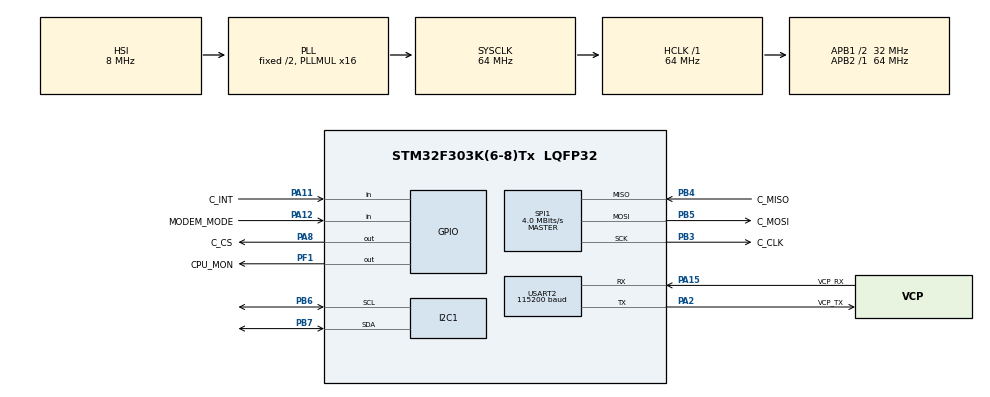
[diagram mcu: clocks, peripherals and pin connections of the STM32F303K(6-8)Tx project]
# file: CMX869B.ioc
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FREERTOS.Tasks01=TaskHK,24,128,StartTaskHK,Default,NULL,Static,TaskHKBuffer,TaskHKControlBlock;TaskCMX869B,48,128,StartTaskCMX869B,Default,NULL,Static,TaskCMX869BBuffer,TaskCMX869BControlBlock
I2C1.Timing=0x10B17DB5
Mcu.Family=STM32F3
Mcu.Name=STM32F303K(6-8)Tx
Mcu.Package=LQFP32
NVIC.PriorityGroup=NVIC_PRIORITYGROUP_4
NVIC.TIM2_IRQn=true\:5\:0\:false\:false\:true\:true\:true\:true\:true
NVIC.TIM6_DAC1_IRQn=true\:15\:0\:false\:false\:true\:false\:false\:true\:true
NVIC.TimeBase=TIM6_DAC1_IRQn
NVIC.TimeBaseIP=TIM6
NVIC.USART2_IRQn=true\:5\:0\:false\:false\:true\:true\:true\:true\:true
PA11.GPIO_Label=C_INT
PA11.Signal=GPIO_Input
PA12.GPIO_Label=MODEM_MODE
PA12.GPIO_PuPd=GPIO_PULLUP
PA12.Signal=GPIO_Input
PA13.GPIO_Label=SWDIO
PA13.Mode=Serial_Wire
PA13.Signal=SYS_JTMS-SWDIO
PA14.GPIO_Label=SWCLK
PA14.Mode=Serial_Wire
PA14.Signal=SYS_JTCK-SWCLK
PA15.GPIO_Label=VCP_RX
PA15.Mode=Asynchronous
PA15.Signal=USART2_RX
PA2.GPIO_Label=VCP_TX
PA2.Mode=Asynchronous
PA2.Signal=USART2_TX
PA8.GPIO_Label=C_CS
PA8.PinState=GPIO_PIN_SET
PA8.Signal=GPIO_Output
PB3.GPIO_Label=C_CLK
PB3.Mode=Full_Duplex_Master
PB3.Signal=SPI1_SCK
PB4.GPIO_Label=C_MISO
PB4.GPIO_PuPd=GPIO_PULLDOWN
PB4.Mode=Full_Duplex_Master
PB4.Signal=SPI1_MISO
PB5.GPIO_Label=C_MOSI
PB5.Mode=Full_Duplex_Master
PB5.Signal=SPI1_MOSI
PB6.Mode=I2C
PB6.Signal=I2C1_SCL
PB7.Mode=I2C
PB7.Signal=I2C1_SDA
PF0\ /\ OSC_IN.GPIO_Label=MCO
PF0\ /\ OSC_IN.Mode=HSE-External-Clock-Source
PF0\ /\ OSC_IN.Signal=RCC_OSC_IN
PF1\ /\ OSC_OUT.GPIO_Label=CPU_MON
PF1\ /\ OSC_OUT.Signal=GPIO_Output
ProjectManager.HeapSize=0x200
ProjectManager.StackSize=0x400
ProjectManager.TargetToolchain=CMake
RCC.AHBFreq_Value=64000000
RCC.APB1CLKDivider=RCC_HCLK_DIV2
RCC.APB1Freq_Value=32000000
RCC.APB1TimFreq_Value=64000000
RCC.APB2Freq_Value=64000000
RCC.APB2TimFreq_Value=64000000
RCC.CortexFreq_Value=64000000
RCC.HCLKFreq_Value=64000000
RCC.HSE_VALUE=8000000
RCC.HSI_VALUE=8000000
RCC.I2c1ClockSelection=RCC_I2C1CLKSOURCE_SYSCLK
RCC.PLLMUL=RCC_PLL_MUL16
RCC.SYSCLKFreq_VALUE=64000000
RCC.SYSCLKSourceVirtual=RCC_SYSCLKSOURCE_PLLCLK
SPI1.BaudRatePrescaler=SPI_BAUDRATEPRESCALER_16
SPI1.CalculateBaudRate=4.0 MBits/s
SPI1.DataSize=SPI_DATASIZE_8BIT
SPI1.Direction=SPI_DIRECTION_2LINES
SPI1.Mode=SPI_MODE_MASTER
SPI1.VirtualType=VM_MASTER
TIM2.AutoReloadPreload=TIM_AUTORELOAD_PRELOAD_ENABLE
TIM2.Period=53333
TIM2.Prescaler=0
USART2.BaudRate=115200
USART2.VirtualMode-Asynchronous=VM_ASYNC
VP_FREERTOS_VS_CMSIS_V2.Mode=CMSIS_V2
VP_SYS_VS_tim6.Mode=TIM6
VP_TIM2_VS_ClockSourceINT.Mode=Internal
board=NUCLEO-F303K8

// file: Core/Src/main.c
/* USER CODE BEGIN Header */
/**
  ******************************************************************************
  * @file           : main.c
  * @brief          : Main program body
  ******************************************************************************
  * @attention
  *
  * Copyright (c) 2025 STMicroelectronics.
  * All rights reserved.
  *
  * This software is licensed under terms that can be found in the LICENSE file
  * in the root directory of this software component.
  * If no LICENSE file comes with this software, it is provided AS-IS.
  *
  ******************************************************************************
  */
/* USER CODE END Header */
#include "main.h"
#include "cmsis_os.h"

/* USER CODE BEGIN Includes */
#include "task.h"
#include "xprintf.h"
#include "TaskCMX869B.h"
#include "TaskHK.h"

/* USER CODE END Includes */

typedef StaticTask_t osStaticThreadDef_t;

I2C_HandleTypeDef hi2c1;

SPI_HandleTypeDef hspi1;

TIM_HandleTypeDef htim2;

UART_HandleTypeDef huart2;

/* Definitions for TaskHK */
osThreadId_t TaskHKHandle;
uint32_t TaskHKBuffer[ 128 ];
osStaticThreadDef_t TaskHKControlBlock;
const osThreadAttr_t TaskHK_attributes = {
  .name = "TaskHK",
  .cb_mem = &TaskHKControlBlock,
  .cb_size = sizeof(TaskHKControlBlock),
  .stack_mem = &TaskHKBuffer[0],
  .stack_size = sizeof(TaskHKBuffer),
  .priority = (osPriority_t) osPriorityNormal,
};
/* Definitions for TaskCMX869B */
osThreadId_t TaskCMX869BHandle;
uint32_t TaskCMX869BBuffer[ 128 ];
osStaticThreadDef_t TaskCMX869BControlBlock;
const osThreadAttr_t TaskCMX869B_attributes = {
  .name = "TaskCMX869B",
  .cb_mem = &TaskCMX869BControlBlock,
  .cb_size = sizeof(TaskCMX869BControlBlock),
  .stack_mem = &TaskCMX869BBuffer[0],
  .stack_size = sizeof(TaskCMX869BBuffer),
  .priority = (osPriority_t) osPriorityRealtime,
};

void SystemClock_Config(void);
static void MX_GPIO_Init(void);
static void MX_I2C1_Init(void);
static void MX_USART2_UART_Init(void);
static void MX_SPI1_Init(void);
static void MX_TIM2_Init(void);
void StartTaskHK(void *argument);
void StartTaskCMX869B(void *argument);

/* USER CODE BEGIN PFP */
void cbus_entry();

/* USER CODE END PFP */

int main(void)
{

  /* MCU Configuration--------------------------------------------------------*/

  /* Reset of all peripherals, Initializes the Flash interface and the Systick. */
  HAL_Init();

  /* USER CODE BEGIN Init */
    // OpenOCDのreset-initがPLL(HSI x16)をSYSCLKにしているので、
    // そのままだとSystemClock_Config()のPLL再設定がHAL_ERRORになる。HSIに戻しておく
    HAL_RCC_DeInit();
  /* USER CODE END Init */

  /* Configure the system clock */
  SystemClock_Config();

  /* Initialize all configured peripherals */
  MX_GPIO_Init();
  MX_I2C1_Init();
  MX_USART2_UART_Init();
  MX_SPI1_Init();
  MX_TIM2_Init();
  /* USER CODE BEGIN 2 */
    // xprintの実働関数の登録,uart_putcはCMX869B.cで定義
    xdev_out(uart_putc);
  /* USER CODE END 2 */

  /* Init scheduler */
  osKernelInitialize();

  /* Create the thread(s) */
  /* creation of TaskHK */
  TaskHKHandle = osThreadNew(StartTaskHK, NULL, &TaskHK_attributes);

  /* creation of TaskCMX869B */
  TaskCMX869BHandle = osThreadNew(StartTaskCMX869B, NULL, &TaskCMX869B_attributes);

  /* Start scheduler */
  osKernelStart();

  /* We should never get here as control is now taken by the scheduler */

  /* Infinite loop */

}

void SystemClock_Config(void)
{
  RCC_OscInitTypeDef RCC_OscInitStruct = {0};
  RCC_ClkInitTypeDef RCC_ClkInitStruct = {0};
  RCC_PeriphCLKInitTypeDef PeriphClkInit = {0};

  /** Initializes the RCC Oscillators according to the specified parameters
  * in the RCC_OscInitTypeDef structure.
  */
  RCC_OscInitStruct.OscillatorType = RCC_OSCILLATORTYPE_HSI;
  RCC_OscInitStruct.HSIState = RCC_HSI_ON;
  RCC_OscInitStruct.HSICalibrationValue = RCC_HSICALIBRATION_DEFAULT;
  RCC_OscInitStruct.PLL.PLLState = RCC_PLL_ON;
  RCC_OscInitStruct.PLL.PLLSource = RCC_PLLSOURCE_HSI;
  RCC_OscInitStruct.PLL.PLLMUL = RCC_PLL_MUL16;
  if (HAL_RCC_OscConfig(&RCC_OscInitStruct) != HAL_OK)
  {
    Error_Handler();
  }

  /** Initializes the CPU, AHB and APB buses clocks
  */
  RCC_ClkInitStruct.ClockType = RCC_CLOCKTYPE_HCLK|RCC_CLOCKTYPE_SYSCLK
                              |RCC_CLOCKTYPE_PCLK1|RCC_CLOCKTYPE_PCLK2;
  RCC_ClkInitStruct.SYSCLKSource = RCC_SYSCLKSOURCE_PLLCLK;
  RCC_ClkInitStruct.AHBCLKDivider = RCC_SYSCLK_DIV1;
  RCC_ClkInitStruct.APB1CLKDivider = RCC_HCLK_DIV2;
  RCC_ClkInitStruct.APB2CLKDivider = RCC_HCLK_DIV1;

  if (HAL_RCC_ClockConfig(&RCC_ClkInitStruct, FLASH_LATENCY_2) != HAL_OK)
  {
    Error_Handler();
  }
  PeriphClkInit.PeriphClockSelection = RCC_PERIPHCLK_I2C1;
  PeriphClkInit.I2c1ClockSelection = RCC_I2C1CLKSOURCE_SYSCLK;
  if (HAL_RCCEx_PeriphCLKConfig(&PeriphClkInit) != HAL_OK)
  {
    Error_Handler();
  }
}

static void MX_I2C1_Init(void)
{

  hi2c1.Instance = I2C1;
  hi2c1.Init.Timing = 0x10B17DB5;
  hi2c1.Init.OwnAddress1 = 0;
  hi2c1.Init.AddressingMode = I2C_ADDRESSINGMODE_7BIT;
  hi2c1.Init.DualAddressMode = I2C_DUALADDRESS_DISABLE;
  hi2c1.Init.OwnAddress2 = 0;
  hi2c1.Init.OwnAddress2Masks = I2C_OA2_NOMASK;
  hi2c1.Init.GeneralCallMode = I2C_GENERALCALL_DISABLE;
  hi2c1.Init.NoStretchMode = I2C_NOSTRETCH_DISABLE;
  if (HAL_I2C_Init(&hi2c1) != HAL_OK)
  {
    Error_Handler();
  }

  /** Configure Analogue filter
  */
  if (HAL_I2CEx_ConfigAnalogFilter(&hi2c1, I2C_ANALOGFILTER_ENABLE) != HAL_OK)
  {
    Error_Handler();
  }

  /** Configure Digital filter
  */
  if (HAL_I2CEx_ConfigDigitalFilter(&hi2c1, 0) != HAL_OK)
  {
    Error_Handler();
  }

}

static void MX_SPI1_Init(void)
{

  /* SPI1 parameter configuration*/
  hspi1.Instance = SPI1;
  hspi1.Init.Mode = SPI_MODE_MASTER;
  hspi1.Init.Direction = SPI_DIRECTION_2LINES;
  hspi1.Init.DataSize = SPI_DATASIZE_8BIT;
  hspi1.Init.CLKPolarity = SPI_POLARITY_LOW;
  hspi1.Init.CLKPhase = SPI_PHASE_1EDGE;
  hspi1.Init.NSS = SPI_NSS_SOFT;
  hspi1.Init.BaudRatePrescaler = SPI_BAUDRATEPRESCALER_16;
  hspi1.Init.FirstBit = SPI_FIRSTBIT_MSB;
  hspi1.Init.TIMode = SPI_TIMODE_DISABLE;
  hspi1.Init.CRCCalculation = SPI_CRCCALCULATION_DISABLE;
  hspi1.Init.CRCPolynomial = 7;
  hspi1.Init.CRCLength = SPI_CRC_LENGTH_DATASIZE;
  hspi1.Init.NSSPMode = SPI_NSS_PULSE_ENABLE;
  if (HAL_SPI_Init(&hspi1) != HAL_OK)
  {
    Error_Handler();
  }

}

static void MX_TIM2_Init(void)
{

  TIM_ClockConfigTypeDef sClockSourceConfig = {0};
  TIM_MasterConfigTypeDef sMasterConfig = {0};

  htim2.Instance = TIM2;
  htim2.Init.Prescaler = 0;
  htim2.Init.CounterMode = TIM_COUNTERMODE_UP;
  htim2.Init.Period = 53333;
  htim2.Init.ClockDivision = TIM_CLOCKDIVISION_DIV1;
  htim2.Init.AutoReloadPreload = TIM_AUTORELOAD_PRELOAD_ENABLE;
  if (HAL_TIM_Base_Init(&htim2) != HAL_OK)
  {
    Error_Handler();
  }
  sClockSourceConfig.ClockSource = TIM_CLOCKSOURCE_INTERNAL;
  if (HAL_TIM_ConfigClockSource(&htim2, &sClockSourceConfig) != HAL_OK)
  {
    Error_Handler();
  }
  sMasterConfig.MasterOutputTrigger = TIM_TRGO_RESET;
  sMasterConfig.MasterSlaveMode = TIM_MASTERSLAVEMODE_DISABLE;
  if (HAL_TIMEx_MasterConfigSynchronization(&htim2, &sMasterConfig) != HAL_OK)
  {
    Error_Handler();
  }

}

static void MX_USART2_UART_Init(void)
{

  huart2.Instance = USART2;
  huart2.Init.BaudRate = 115200;
  huart2.Init.WordLength = UART_WORDLENGTH_8B;
  huart2.Init.StopBits = UART_STOPBITS_1;
  huart2.Init.Parity = UART_PARITY_NONE;
  huart2.Init.Mode = UART_MODE_TX_RX;
  huart2.Init.HwFlowCtl = UART_HWCONTROL_NONE;
  huart2.Init.OverSampling = UART_OVERSAMPLING_16;
  huart2.Init.OneBitSampling = UART_ONE_BIT_SAMPLE_DISABLE;
  huart2.AdvancedInit.AdvFeatureInit = UART_ADVFEATURE_NO_INIT;
  if (HAL_UART_Init(&huart2) != HAL_OK)
  {
    Error_Handler();
  }

}

static void MX_GPIO_Init(void)
{
  GPIO_InitTypeDef GPIO_InitStruct = {0};

  /* GPIO Ports Clock Enable */
  __HAL_RCC_GPIOF_CLK_ENABLE();
  __HAL_RCC_GPIOA_CLK_ENABLE();
  __HAL_RCC_GPIOB_CLK_ENABLE();

  /*Configure GPIO pin Output Level */
  HAL_GPIO_WritePin(CPU_MON_GPIO_Port, CPU_MON_Pin, GPIO_PIN_RESET);

  /*Configure GPIO pin Output Level */
  HAL_GPIO_WritePin(C_CS_GPIO_Port, C_CS_Pin, GPIO_PIN_SET);

  /*Configure GPIO pin : CPU_MON_Pin */
  GPIO_InitStruct.Pin = CPU_MON_Pin;
  GPIO_InitStruct.Mode = GPIO_MODE_OUTPUT_PP;
  GPIO_InitStruct.Pull = GPIO_NOPULL;
  GPIO_InitStruct.Speed = GPIO_SPEED_FREQ_LOW;
  HAL_GPIO_Init(CPU_MON_GPIO_Port, &GPIO_InitStruct);

  /*Configure GPIO pin : C_CS_Pin */
  GPIO_InitStruct.Pin = C_CS_Pin;
  GPIO_InitStruct.Mode = GPIO_MODE_OUTPUT_PP;
  GPIO_InitStruct.Pull = GPIO_NOPULL;
  GPIO_InitStruct.Speed = GPIO_SPEED_FREQ_LOW;
  HAL_GPIO_Init(C_CS_GPIO_Port, &GPIO_InitStruct);

  /*Configure GPIO pin : C_INT_Pin */
  GPIO_InitStruct.Pin = C_INT_Pin;
  GPIO_InitStruct.Mode = GPIO_MODE_INPUT;
  GPIO_InitStruct.Pull = GPIO_NOPULL;
  HAL_GPIO_Init(C_INT_GPIO_Port, &GPIO_InitStruct);

  /*Configure GPIO pin : MODEM_MODE_Pin */
  GPIO_InitStruct.Pin = MODEM_MODE_Pin;
  GPIO_InitStruct.Mode = GPIO_MODE_INPUT;
  GPIO_InitStruct.Pull = GPIO_PULLUP;
  HAL_GPIO_Init(MODEM_MODE_GPIO_Port, &GPIO_InitStruct);

}

/* USER CODE BEGIN 4 */
//************************
// 外部割り込み対策
//************************

/* USER CODE END 4 */

void StartTaskHK(void *argument)
{
  /* USER CODE BEGIN 5 */
    /* Infinite loop */
    for (;;) {
        TaskHKEntry(argument);
    }
  /* USER CODE END 5 */
}

void StartTaskCMX869B(void *argument)
{
  /* USER CODE BEGIN StartTaskCMX869B */
    /* Infinite loop */
    for (;;) {
        TaskCMX869BEntry(argument);
    }
  /* USER CODE END StartTaskCMX869B */
}

void HAL_TIM_PeriodElapsedCallback(TIM_HandleTypeDef *htim)
{
  if (htim->Instance == TIM6)
  {
    HAL_IncTick();
  }
  /* USER CODE BEGIN Callback 1 */
    if (htim->Instance == TIM2) {
        BaseType_t xHigherPriorityTaskWoken = pdFALSE;
        vTaskNotifyGiveFromISR(TaskCMX869BHandle, &xHigherPriorityTaskWoken);
        portYIELD_FROM_ISR(xHigherPriorityTaskWoken);
    }
  /* USER CODE END Callback 1 */
}

void Error_Handler(void)
{
    __disable_irq();
    while (1) {
    }
}
